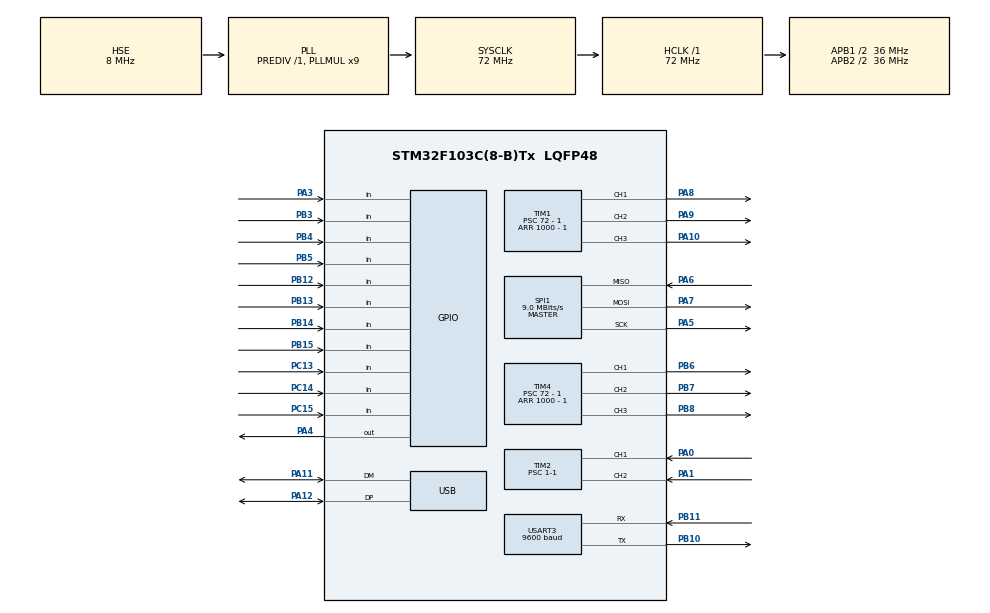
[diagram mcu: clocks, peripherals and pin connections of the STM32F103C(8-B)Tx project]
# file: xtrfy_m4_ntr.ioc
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Mcu.Family=STM32F1
Mcu.Name=STM32F103C(8-B)Tx
Mcu.Package=LQFP48
NVIC.PriorityGroup=NVIC_PRIORITYGROUP_4
NVIC.TIM2_IRQn=true\:0\:0\:false\:false\:true\:true\:true\:true
NVIC.TIM4_IRQn=true\:0\:0\:false\:false\:true\:true\:true\:true
NVIC.USB_LP_CAN1_RX0_IRQn=true\:0\:0\:false\:false\:true\:false\:true\:true
PA0-WKUP.GPIO_PuPd=GPIO_PULLUP
PA0-WKUP.Signal=S_TIM2_CH1_ETR
PA1.GPIO_PuPd=GPIO_PULLUP
PA1.Signal=S_TIM2_CH2
PA10.GPIO_Speed=GPIO_SPEED_FREQ_LOW
PA10.Signal=S_TIM1_CH3
PA11.Mode=Device
PA11.Signal=USB_DM
PA12.Mode=Device
PA12.Signal=USB_DP
PA13.Mode=Serial_Wire
PA13.Signal=SYS_JTMS-SWDIO
PA14.Mode=Serial_Wire
PA14.Signal=SYS_JTCK-SWCLK
PA3.Signal=GPIO_Input
PA4.Signal=GPIO_Output
PA5.Mode=Full_Duplex_Master
PA5.Signal=SPI1_SCK
PA6.Mode=Full_Duplex_Master
PA6.Signal=SPI1_MISO
PA7.Mode=Full_Duplex_Master
PA7.Signal=SPI1_MOSI
PA8.GPIO_Speed=GPIO_SPEED_FREQ_LOW
PA8.Signal=S_TIM1_CH1
PA9.GPIO_Speed=GPIO_SPEED_FREQ_LOW
PA9.Signal=S_TIM1_CH2
PB10.Mode=Asynchronous
PB10.Signal=USART3_TX
PB11.Mode=Asynchronous
PB11.Signal=USART3_RX
PB12.Signal=GPIO_Input
PB13.Signal=GPIO_Input
PB14.Signal=GPIO_Input
PB15.Signal=GPIO_Input
PB3.Signal=GPIO_Input
PB4.Signal=GPIO_Input
PB5.Signal=GPIO_Input
PB6.Signal=S_TIM4_CH1
PB7.Signal=S_TIM4_CH2
PB8.Signal=S_TIM4_CH3
PC13-TAMPER-RTC.GPIO_PuPd=GPIO_PULLUP
PC13-TAMPER-RTC.Signal=GPIO_Input
PC14-OSC32_IN.GPIO_PuPd=GPIO_PULLUP
PC14-OSC32_IN.Signal=GPIO_Input
PC15-OSC32_OUT.GPIO_PuPd=GPIO_PULLUP
PC15-OSC32_OUT.Signal=GPIO_Input
PD0-OSC_IN.Mode=HSE-External-Oscillator
PD0-OSC_IN.Signal=RCC_OSC_IN
PD1-OSC_OUT.Mode=HSE-External-Oscillator
PD1-OSC_OUT.Signal=RCC_OSC_OUT
ProjectManager.HeapSize=0x1000
ProjectManager.StackSize=0x1000
ProjectManager.TargetToolchain=MDK-ARM V5
RCC.AHBFreq_Value=72000000
RCC.APB1CLKDivider=RCC_HCLK_DIV2
RCC.APB1Freq_Value=36000000
RCC.APB1TimFreq_Value=72000000
RCC.APB2CLKDivider=RCC_HCLK_DIV2
RCC.APB2Freq_Value=36000000
RCC.APB2TimFreq_Value=72000000
RCC.HCLKFreq_Value=72000000
RCC.PLLMUL=RCC_PLL_MUL9
RCC.SYSCLKFreq_VALUE=72000000
RCC.SYSCLKSource=RCC_SYSCLKSOURCE_PLLCLK
RCC.USBFreq_Value=48000000
RCC.USBPrescaler=RCC_USBCLKSOURCE_PLL_DIV1_5
SH.S_TIM1_CH1.0=TIM1_CH1,PWM Generation1 CH1
SH.S_TIM1_CH2.0=TIM1_CH2,PWM Generation2 CH2
SH.S_TIM1_CH3.0=TIM1_CH3,PWM Generation3 CH3
SH.S_TIM2_CH1_ETR.0=TIM2_CH1,Encoder_Interface
SH.S_TIM2_CH2.0=TIM2_CH2,Encoder_Interface
SH.S_TIM4_CH1.0=TIM4_CH1,PWM Generation1 CH1
SH.S_TIM4_CH2.0=TIM4_CH2,PWM Generation2 CH2
SH.S_TIM4_CH3.0=TIM4_CH3,PWM Generation3 CH3
SPI1.BaudRatePrescaler=SPI_BAUDRATEPRESCALER_4
SPI1.CLKPhase=SPI_PHASE_2EDGE
SPI1.CLKPolarity=SPI_POLARITY_HIGH
SPI1.CalculateBaudRate=9.0 MBits/s
SPI1.Direction=SPI_DIRECTION_2LINES
SPI1.Mode=SPI_MODE_MASTER
SPI1.VirtualType=VM_MASTER
TIM1.AutoReloadPreload=TIM_AUTORELOAD_PRELOAD_ENABLE
TIM1.Channel-PWM\ Generation1\ CH1=TIM_CHANNEL_1
TIM1.Channel-PWM\ Generation2\ CH2=TIM_CHANNEL_2
TIM1.Channel-PWM\ Generation3\ CH3=TIM_CHANNEL_3
TIM1.Period=1000 - 1
TIM1.Prescaler=72 - 1
TIM2.AutoReloadPreload=TIM_AUTORELOAD_PRELOAD_ENABLE
TIM2.EncoderMode=TIM_ENCODERMODE_TI12
TIM2.IC1Filter=15
TIM2.IC1Polarity=TIM_ICPOLARITY_FALLING
TIM2.IC2Filter=15
TIM2.IC2Polarity=TIM_ICPOLARITY_FALLING
TIM2.Period=65536-1
TIM2.Prescaler=1-1
TIM4.AutoReloadPreload=TIM_AUTORELOAD_PRELOAD_ENABLE
TIM4.Channel-PWM\ Generation1\ CH1=TIM_CHANNEL_1
TIM4.Channel-PWM\ Generation2\ CH2=TIM_CHANNEL_2
TIM4.Channel-PWM\ Generation3\ CH3=TIM_CHANNEL_3
TIM4.Period=1000 - 1
TIM4.Prescaler=72 - 1
USART3.BaudRate=9600
USART3.VirtualMode=VM_ASYNC
USB_DEVICE.CLASS_NAME_FS=HID
USB_DEVICE.VirtualMode=Hid
USB_DEVICE.VirtualModeFS=Hid_FS
VP_RTC_No_RTC_Output.Mode=RTC_OUT_NO
VP_RTC_VS_RTC_Activate.Mode=RTC_Enabled
VP_TIM1_VS_ClockSourceINT.Mode=Internal
VP_TIM4_VS_ClockSourceINT.Mode=Internal
VP_USB_DEVICE_VS_USB_DEVICE_HID_FS.Mode=HID_FS
board=custom

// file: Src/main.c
/* USER CODE BEGIN Header */
/**
  ******************************************************************************
  * @file           : main.c
  * @brief          : Main program body
  ******************************************************************************
  * @attention
  *
  * Copyright (c) 2023 STMicroelectronics.
  * All rights reserved.
  *
  * This software is licensed under terms that can be found in the LICENSE file
  * in the root directory of this software component.
  * If no LICENSE file comes with this software, it is provided AS-IS.
  *
  ******************************************************************************
  */
/* USER CODE END Header */
#include "main.h"
#include "rtc.h"
#include "spi.h"
#include "tim.h"
#include "usart.h"
#include "usb_device.h"
#include "gpio.h"

/* USER CODE BEGIN Includes */
#include "delay.h"
#include "app.h"
#include "led.h"
#include "enc.h"
/* USER CODE END Includes */

/* USER CODE BEGIN PV */
extern TIM_HandleTypeDef htim1;
extern TIM_HandleTypeDef htim4;

/* USER CODE END PV */

void SystemClock_Config(void);

int main(void)
{

  /* MCU Configuration--------------------------------------------------------*/

  /* Reset of all peripherals, Initializes the Flash interface and the Systick. */
  HAL_Init();

  /* Configure the system clock */
  SystemClock_Config();

  /* Initialize all configured peripherals */
  MX_GPIO_Init();
  MX_SPI1_Init();
  MX_TIM1_Init();
  MX_TIM2_Init();
  MX_TIM4_Init();
  MX_USART3_UART_Init();
  MX_USB_DEVICE_Init();
  MX_RTC_Init();
  /* USER CODE BEGIN 2 */
    HAL_TIM_Base_Start_IT(&htim1);
    HAL_TIM_Base_Start_IT(&htim4);

    delay_init();
    init_enc();
    init_rgb_main();
    init_rgb_cpi();

  /* USER CODE END 2 */

  /* Infinite loop */
  /* USER CODE BEGIN WHILE */
    user_init();

  while (1)
  {
    main_loop();
    /* USER CODE END WHILE */

  }
}

void SystemClock_Config(void)
{
  RCC_OscInitTypeDef RCC_OscInitStruct = {0};
  RCC_ClkInitTypeDef RCC_ClkInitStruct = {0};
  RCC_PeriphCLKInitTypeDef PeriphClkInit = {0};

  /** Initializes the RCC Oscillators according to the specified parameters
  * in the RCC_OscInitTypeDef structure.
  */
  RCC_OscInitStruct.OscillatorType = RCC_OSCILLATORTYPE_LSI|RCC_OSCILLATORTYPE_HSE;
  RCC_OscInitStruct.HSEState = RCC_HSE_ON;
  RCC_OscInitStruct.HSEPredivValue = RCC_HSE_PREDIV_DIV1;
  RCC_OscInitStruct.HSIState = RCC_HSI_ON;
  RCC_OscInitStruct.LSIState = RCC_LSI_ON;
  RCC_OscInitStruct.PLL.PLLState = RCC_PLL_ON;
  RCC_OscInitStruct.PLL.PLLSource = RCC_PLLSOURCE_HSE;
  RCC_OscInitStruct.PLL.PLLMUL = RCC_PLL_MUL9;
  if (HAL_RCC_OscConfig(&RCC_OscInitStruct) != HAL_OK)
  {
    Error_Handler();
  }

  /** Initializes the CPU, AHB and APB buses clocks
  */
  RCC_ClkInitStruct.ClockType = RCC_CLOCKTYPE_HCLK|RCC_CLOCKTYPE_SYSCLK
                              |RCC_CLOCKTYPE_PCLK1|RCC_CLOCKTYPE_PCLK2;
  RCC_ClkInitStruct.SYSCLKSource = RCC_SYSCLKSOURCE_PLLCLK;
  RCC_ClkInitStruct.AHBCLKDivider = RCC_SYSCLK_DIV1;
  RCC_ClkInitStruct.APB1CLKDivider = RCC_HCLK_DIV2;
  RCC_ClkInitStruct.APB2CLKDivider = RCC_HCLK_DIV2;

  if (HAL_RCC_ClockConfig(&RCC_ClkInitStruct, FLASH_LATENCY_2) != HAL_OK)
  {
    Error_Handler();
  }
  PeriphClkInit.PeriphClockSelection = RCC_PERIPHCLK_RTC|RCC_PERIPHCLK_USB;
  PeriphClkInit.RTCClockSelection = RCC_RTCCLKSOURCE_LSI;
  PeriphClkInit.UsbClockSelection = RCC_USBCLKSOURCE_PLL_DIV1_5;
  if (HAL_RCCEx_PeriphCLKConfig(&PeriphClkInit) != HAL_OK)
  {
    Error_Handler();
  }
}

void Error_Handler(void)
{
  __disable_irq();
  while (1)
  {
  }
}
